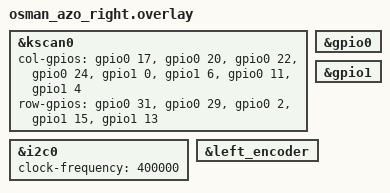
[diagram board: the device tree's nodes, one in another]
#include "osman_azo.dtsi"

&kscan0 {
    col-gpios = <&gpio0 17 (GPIO_ACTIVE_HIGH | GPIO_PULL_DOWN)>
              , <&gpio0 20 (GPIO_ACTIVE_HIGH | GPIO_PULL_DOWN)>
              , <&gpio0 22 (GPIO_ACTIVE_HIGH | GPIO_PULL_DOWN)>
              , <&gpio0 24 (GPIO_ACTIVE_HIGH | GPIO_PULL_DOWN)>
              , <&gpio1 0 (GPIO_ACTIVE_HIGH | GPIO_PULL_DOWN)>
              , <&gpio1 6 (GPIO_ACTIVE_HIGH | GPIO_PULL_DOWN)>
              , <&gpio0 11 (GPIO_ACTIVE_HIGH | GPIO_PULL_DOWN)>
              , <&gpio1 4 (GPIO_ACTIVE_HIGH | GPIO_PULL_DOWN)>
              ;
    row-gpios = <&gpio0 31 (GPIO_ACTIVE_HIGH | GPIO_PULL_DOWN)>
              , <&gpio0 29 (GPIO_ACTIVE_HIGH | GPIO_PULL_DOWN)>
              , <&gpio0 2 (GPIO_ACTIVE_HIGH | GPIO_PULL_DOWN)>
              , <&gpio1 15 (GPIO_ACTIVE_HIGH | GPIO_PULL_DOWN)>
              , <&gpio1 13 (GPIO_ACTIVE_HIGH | GPIO_PULL_DOWN)>
              ;
};

&gpio0 {
    status = "okay";
};

&gpio1 {
    status = "okay";
};

&i2c0 {
    status = "okay";
    clock-frequency = <400000>;
};

&left_encoder {
    status = "okay";
};
